# STM32WB5Mxx register map
File version: 1.0
Registers are 32-bit, read-write, reset 0x0 unless marked. A register's access mark holds for its fields unless they carry their own. Offsets are from the block's base; [hi:lo] are bit positions; lines under a group give offsets from that group; {n}, {i} and the like mark numbered series; 'fields as' and 'values as' point back to an identical list.

## DMAMUX1 — DMA Multiplexer
Base 0x40020800
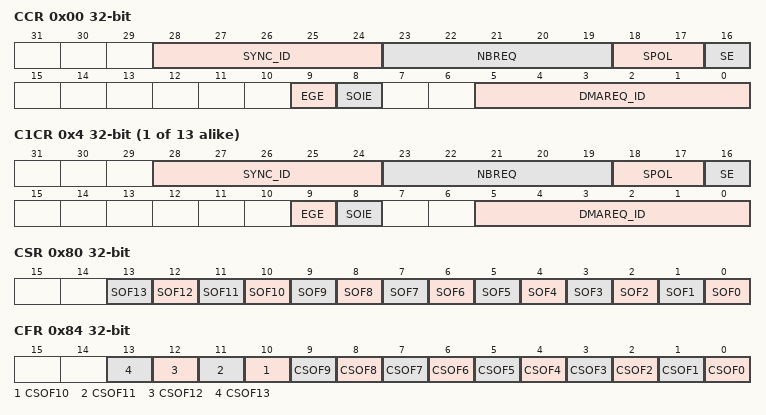
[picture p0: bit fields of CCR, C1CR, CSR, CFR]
0x00 CCR — DMA Multiplexer Channel x Control Register
  [28:24] SYNC_ID — Synchronization ID
  [23:19] NBREQ — Number of request
  [18:17] SPOL — Synchronization polarity
  [16] SE — Synchronization enable
  [9] EGE — Event generation interrupt enable
  [8] SOIE — Synchro overrun interrupt enable
  [5:0] DMAREQ_ID — DMA Request ID
{0x0+4i} C{i}CR (i=1..13) — DMA Multiplexer Channel x Control Register
  fields as CCR
0x80 CSR — DMA Channel Status Register
  [n] SOF{n} (n=0..13) — Synchronization Overrun Flag {n}
0x84 CFR — DMA Channel Clear Flag Register
  [n] CSOF{n} (n=0..13) — Clear Overrun Flag {n}
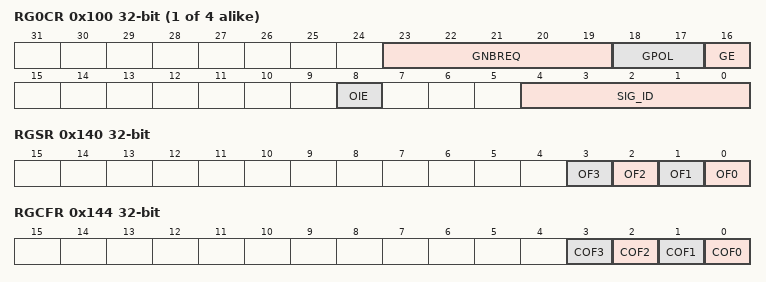
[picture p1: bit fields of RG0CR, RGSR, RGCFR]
{0x100+4i} RG{i}CR (i=0..3) — DMA Request Generator x Control Register
  [23:19] GNBREQ — Number of request
  [18:17] GPOL — Generation polarity
  [16] GE — Generation enable
  [8] OIE — Overrun interrupt enable
  [4:0] SIG_ID — Signal ID
0x140 RGSR — DMA Request Generator Status Register
  [n] OF{n} (n=0..3) — Overrun flag {n}
0x144 RGCFR — DMA Request Generator Clear Flag Register
  [n] COF{n} (n=0..3) — Clear Overrun flag {n}

## CRC — CRC calculation unit
Base 0x40023000
0x00 DR — CRC Data register
  [31:0] DR — Data register bits
0x04 IDR — CRC Independent data register
  [31:0] IDR — General-purpose 8-bits data register bits
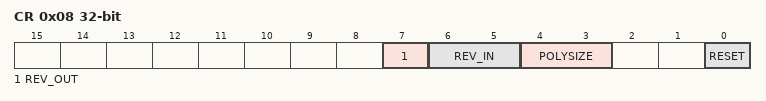
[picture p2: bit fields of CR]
0x08 CR — CRC Control register
  [7] REV_OUT — REV_OUT Reverse Output Data bits
    0=NONE (Output Data bit order not affected); 1=BIT (Output Data bit reversal done by bit)
  [6:5] REV_IN — REV_IN Reverse Input Data bits
    0=NONE (Input Data bit order not affected); 1=BYTE (Input Data bit reversal done by byte); 2=HALFWORD (Input Data bit reversal done by half-word); 3=WORD (Input Data bit reversal done by word)
  [4:3] POLYSIZE — Polynomial size bits
    0=POLYLENGTH_32B (32 bits Polynomial size); 1=POLYLENGTH_16B (16 bits Polynomial size); 2=POLYLENGTH_8B (8 bits Polynomial size); 3=POLYLENGTH_7B (7 bits Polynomial size)
  [0] RESET — RESET the CRC computation unit bit
0x10 INIT — Initial CRC value register
  [31:0] INIT — Initial CRC value bits
0x14 POL — CRC polynomial register
  [31:0] POL — Coefficients of the polynomial

## TSC — Touch Sensing Controller (TSC)
Base 0x40024000
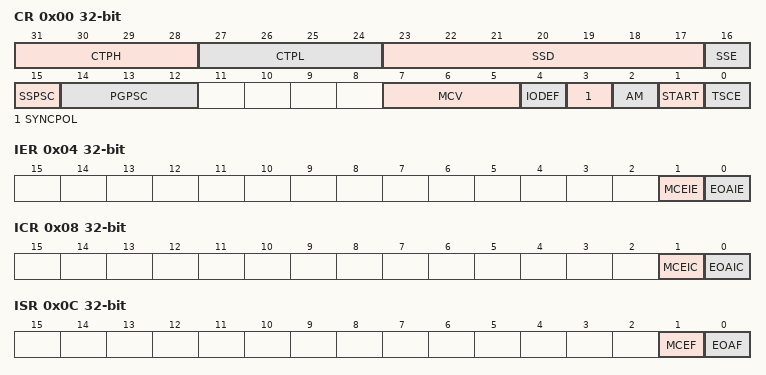
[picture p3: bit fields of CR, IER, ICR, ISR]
0x00 CR — TSC control register
  [31:28] CTPH — CTPH[3:0] bits (Charge Transfer pulse high)
  [27:24] CTPL — CTPL[3:0] bits (Charge Transfer pulse low)
  [23:17] SSD — SSD[6:0] bits (Spread Spectrum Deviation)
  [16] SSE — Spread Spectrum Enable
  [15] SSPSC — Spread Spectrum Prescaler
  [14:12] PGPSC — PGPSC[2:0] bits (Pulse Generator Prescaler)
  [7:5] MCV — MCV[2:0] bits (Max Count Value)
  [4] IODEF — IO default mode
  [3] SYNCPOL — Synchronization pin polarity
  [2] AM — Acquisition mode
  [1] START — Start a new acquisition
  [0] TSCE — Touch sensing controller enable
0x04 IER — TSC interrupt enable register
  [1] MCEIE — Max count error interrupt enable
  [0] EOAIE — End of acquisition interrupt enable
0x08 ICR — TSC interrupt clear register
  [1] MCEIC — Max count error interrupt clear
  [0] EOAIC — End of acquisition interrupt clear
0x0C ISR — TSC interrupt status register
  [1] MCEF — Max count error flag
  [0] EOAF — End of acquisition flag
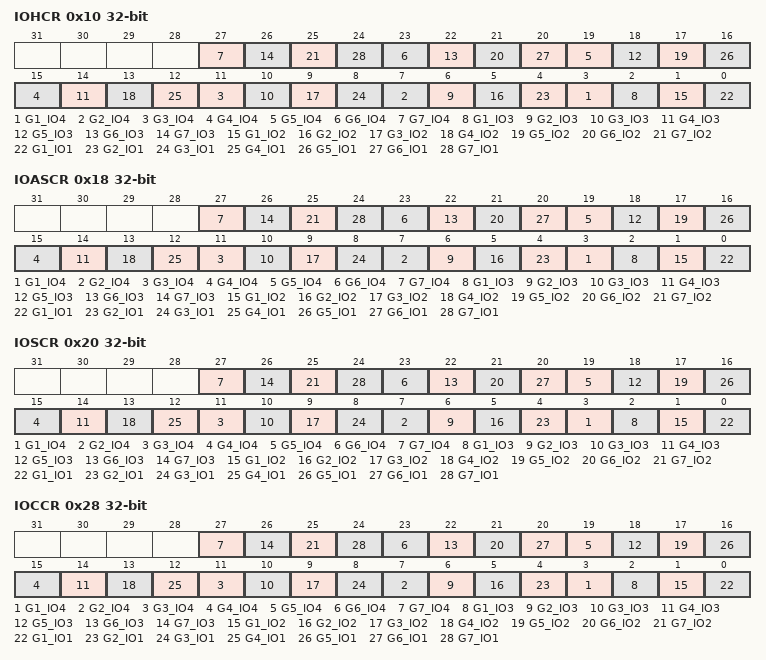
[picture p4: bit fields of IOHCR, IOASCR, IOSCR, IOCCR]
0x10 IOHCR — TSC I/O hysteresis control register
  [4n-1] G{n}_IO4 (n=1..7) — GROUP{n}_IO4 schmitt trigger hysteresis mode
  [4n-2] G{n}_IO3 (n=1..7) — GROUP{n}_IO3 schmitt trigger hysteresis mode
  [4n-3] G{n}_IO2 (n=1..7) — GROUP{n}_IO2 schmitt trigger hysteresis mode
  [4n-4] G{n}_IO1 (n=1..7) — GROUP{n}_IO1 schmitt trigger hysteresis mode
0x18 IOASCR — TSC I/O analog switch control register
  [4n-1] G{n}_IO4 (n=1..7) — GROUP{n}_IO4 analog switch enable
  [4n-2] G{n}_IO3 (n=1..7) — GROUP{n}_IO3 analog switch enable
  [4n-3] G{n}_IO2 (n=1..7) — GROUP{n}_IO2 analog switch enable
  [4n-4] G{n}_IO1 (n=1..7) — GROUP{n}_IO1 analog switch enable
0x20 IOSCR — TSC I/O sampling control register
  [4n-1] G{n}_IO4 (n=1..7) — GROUP{n}_IO4 sampling mode
  [4n-2] G{n}_IO3 (n=1..7) — GROUP{n}_IO3 sampling mode
  [4n-3] G{n}_IO2 (n=1..7) — GROUP{n}_IO2 sampling mode
  [4n-4] G{n}_IO1 (n=1..7) — GROUP{n}_IO1 sampling mode
0x28 IOCCR — TSC I/O channel control register
  [4n-1] G{n}_IO4 (n=1..7) — GROUP{n}_IO4 channel mode
  [4n-2] G{n}_IO3 (n=1..7) — GROUP{n}_IO3 channel mode
  [4n-3] G{n}_IO2 (n=1..7) — GROUP{n}_IO2 channel mode
  [4n-4] G{n}_IO1 (n=1..7) — GROUP{n}_IO1 channel mode
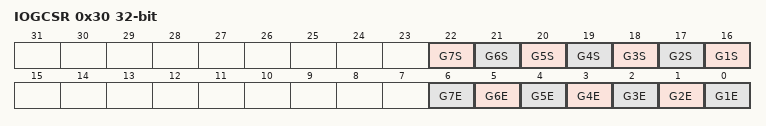
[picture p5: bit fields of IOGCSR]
0x30 IOGCSR — TSC I/O group control status register
  [n+15] G{n}S (n=1..7) — Analog IO GROUP{n} status
  [n-1] G{n}E (n=1..7) — Analog IO GROUP{n} enable
{0x30+4i} IOG{i}CR (i=1..7) — TSC I/O group x counter register
  [13:0] CNT — CNT[13:0] bits (Counter value)
